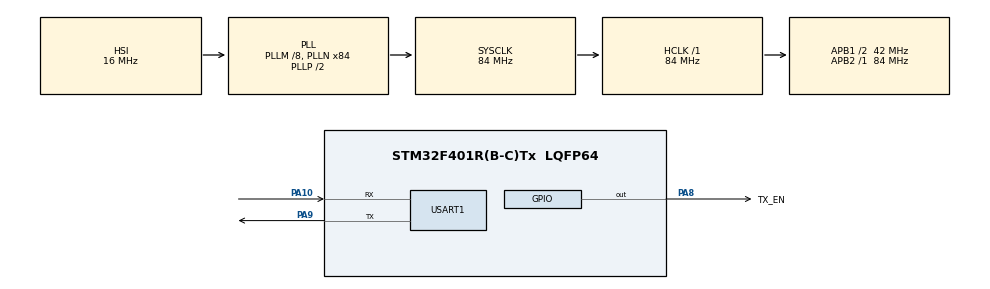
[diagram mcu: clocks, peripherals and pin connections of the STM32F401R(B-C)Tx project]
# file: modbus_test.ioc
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Mcu.Family=STM32F4
Mcu.Name=STM32F401R(B-C)Tx
Mcu.Package=LQFP64
NVIC.PriorityGroup=NVIC_PRIORITYGROUP_4
NVIC.USART1_IRQn=true\:0\:0\:false\:false\:true\:true\:true\:true
PA10.Mode=Asynchronous
PA10.Signal=USART1_RX
PA13.Mode=Serial_Wire
PA13.Signal=SYS_JTMS-SWDIO
PA14.Mode=Serial_Wire
PA14.Signal=SYS_JTCK-SWCLK
PA8.GPIO_Label=TX_EN
PA8.Signal=GPIO_Output
PA9.Mode=Asynchronous
PA9.Signal=USART1_TX
PH0\ -\ OSC_IN.Mode=HSE-External-Oscillator
PH0\ -\ OSC_IN.Signal=RCC_OSC_IN
PH1\ -\ OSC_OUT.Mode=HSE-External-Oscillator
PH1\ -\ OSC_OUT.Signal=RCC_OSC_OUT
ProjectManager.HeapSize=0x200
ProjectManager.StackSize=0x400
ProjectManager.TargetToolchain=STM32CubeIDE
RCC.48MHZClocksFreq_Value=42000000
RCC.AHBFreq_Value=84000000
RCC.APB1CLKDivider=RCC_HCLK_DIV2
RCC.APB1Freq_Value=42000000
RCC.APB1TimFreq_Value=84000000
RCC.APB2Freq_Value=84000000
RCC.APB2TimFreq_Value=84000000
RCC.CortexFreq_Value=84000000
RCC.HCLKFreq_Value=84000000
RCC.HSE_VALUE=25000000
RCC.HSI_VALUE=16000000
RCC.LSE_VALUE=32768
RCC.PLLM=8
RCC.PLLN=84
RCC.SYSCLKFreq_VALUE=84000000
RCC.SYSCLKSource=RCC_SYSCLKSOURCE_PLLCLK
RCC.VCOOutputFreq_Value=168000000
USART1.VirtualMode=VM_ASYNC
board=custom

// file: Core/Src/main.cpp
/* USER CODE BEGIN Header */
/**
  ******************************************************************************
  * @file           : main.c
  * @brief          : Main program body
  ******************************************************************************
  * @attention
  *
  * Copyright (c) 2026 STMicroelectronics.
  * All rights reserved.
  *
  * This software is licensed under terms that can be found in the LICENSE file
  * in the root directory of this software component.
  * If no LICENSE file comes with this software, it is provided AS-IS.
  *
  ******************************************************************************
  */
/* USER CODE END Header */
#include "main.h"
#include "usart.h"
#include "gpio.h"

/* USER CODE BEGIN Includes */
#include "modbus_crc.h"
/* USER CODE END Includes */

void SystemClock_Config(void);

/* USER CODE BEGIN 0 */
uint8_t RxData[32];
uint8_t TxData[8];
uint16_t Data[10];

void sendData(uint8_t *data)
{
    HAL_GPIO_WritePin(TX_EN_GPIO_Port, TX_EN_Pin, GPIO_PIN_SET);
    HAL_Delay(1);
    HAL_UART_Transmit(&huart1, data, 8, 1000);
    HAL_Delay(2);
    HAL_GPIO_WritePin(TX_EN_GPIO_Port, TX_EN_Pin, GPIO_PIN_RESET);
}

void receiveData(void)
{
    // FC01 response: addr(1) + func(1) + bytecount(1) + data(2) + crc(2) = 7 bytes
    // for 10 coils: bytecount=2, so total = 7 bytes
    HAL_UART_Receive(&huart1, RxData, 7, 1000);
}

void buildReadCoils(void)
{
    TxData[0] = 0x05;  // Slave ID
    TxData[1] = 0x01;  // FC01 = Read Coils
    TxData[2] = 0x00;  // Start Address HIGH
    TxData[3] = 0x00;  // Start Address LOW
    TxData[4] = 0x00;  // Quantity HIGH
    TxData[5] = 0x0A;  // Quantity LOW = 10
    uint16_t crc = crc16(TxData, 6);
    TxData[6] = crc & 0xFF;
    TxData[7] = (crc >> 8) & 0xFF;
}
/* USER CODE END 0 */
int main(void)
{

  /* MCU Configuration--------------------------------------------------------*/

  /* Reset of all peripherals, Initializes the Flash interface and the Systick. */
  HAL_Init();

  /* Configure the system clock */
  SystemClock_Config();

  /* Initialize all configured peripherals */
  MX_GPIO_Init();
  MX_USART1_UART_Init();

  /* USER CODE BEGIN 2 */
    buildReadCoils();
    /* USER CODE END 2 */

    while (1)
    {
      /* USER CODE BEGIN 3 */
      sendData(TxData);
      HAL_Delay(5);         // استنى RS485 يرجع لـ RX mode
      receiveData();
      HAL_Delay(500);       // انتظر نص ثانية قبل request جديدة
      /* USER CODE END 3 */
    }
    /* USER CODE END 3 */
}

void SystemClock_Config(void)
{
  RCC_OscInitTypeDef RCC_OscInitStruct = {0};
  RCC_ClkInitTypeDef RCC_ClkInitStruct = {0};

  /** Configure the main internal regulator output voltage
  */
  __HAL_RCC_PWR_CLK_ENABLE();
  __HAL_PWR_VOLTAGESCALING_CONFIG(PWR_REGULATOR_VOLTAGE_SCALE2);

  /** Initializes the RCC Oscillators according to the specified parameters
  * in the RCC_OscInitTypeDef structure.
  */
  RCC_OscInitStruct.OscillatorType = RCC_OSCILLATORTYPE_HSI;
  RCC_OscInitStruct.HSIState = RCC_HSI_ON;
  RCC_OscInitStruct.HSICalibrationValue = RCC_HSICALIBRATION_DEFAULT;
  RCC_OscInitStruct.PLL.PLLState = RCC_PLL_ON;
  RCC_OscInitStruct.PLL.PLLSource = RCC_PLLSOURCE_HSI;
  RCC_OscInitStruct.PLL.PLLM = 8;
  RCC_OscInitStruct.PLL.PLLN = 84;
  RCC_OscInitStruct.PLL.PLLP = RCC_PLLP_DIV2;
  RCC_OscInitStruct.PLL.PLLQ = 4;
  if (HAL_RCC_OscConfig(&RCC_OscInitStruct) != HAL_OK)
  {
    Error_Handler();
  }

  /** Initializes the CPU, AHB and APB buses clocks
  */
  RCC_ClkInitStruct.ClockType = RCC_CLOCKTYPE_HCLK|RCC_CLOCKTYPE_SYSCLK
                              |RCC_CLOCKTYPE_PCLK1|RCC_CLOCKTYPE_PCLK2;
  RCC_ClkInitStruct.SYSCLKSource = RCC_SYSCLKSOURCE_PLLCLK;
  RCC_ClkInitStruct.AHBCLKDivider = RCC_SYSCLK_DIV1;
  RCC_ClkInitStruct.APB1CLKDivider = RCC_HCLK_DIV2;
  RCC_ClkInitStruct.APB2CLKDivider = RCC_HCLK_DIV1;

  if (HAL_RCC_ClockConfig(&RCC_ClkInitStruct, FLASH_LATENCY_2) != HAL_OK)
  {
    Error_Handler();
  }
}

void Error_Handler(void)
{
  __disable_irq();
  while (1)
  {
  }
}
